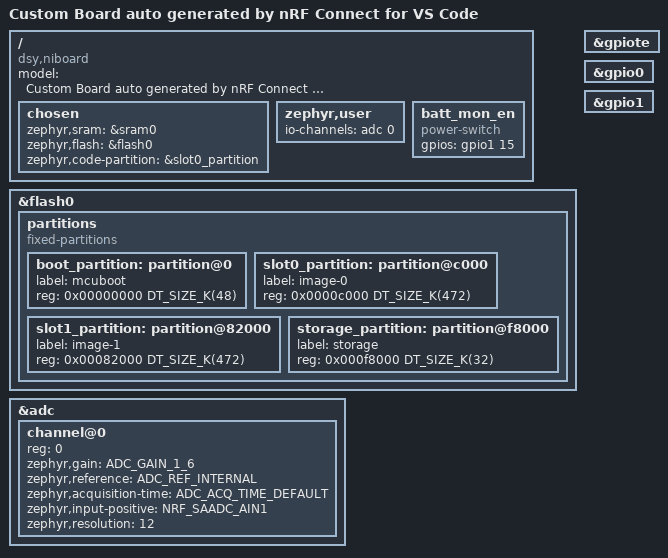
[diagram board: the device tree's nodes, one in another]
/dts-v1/;
#include <nordic/nrf52840_qfaa.dtsi>


/ {
	model = "Custom Board auto generated by nRF Connect for VS Code";
	compatible = "dsy,niboard";

	chosen {
		zephyr,sram = &sram0;
		zephyr,flash = &flash0;
		zephyr,code-partition = &slot0_partition;
	};
	zephyr,user {
        io-channels = <&adc 0>;
    };

	batt_mon_en: batt_mon_en {
		compatible = "power-switch";
        status = "okay";
		gpios= <&gpio1 15 GPIO_ACTIVE_HIGH>;
	};
};

&flash0 {
	partitions {
		compatible = "fixed-partitions";
		#address-cells = <1>;
		#size-cells = <1>;

		boot_partition: partition@0 {
			label = "mcuboot";
			reg = <0x00000000 DT_SIZE_K(48)>;
		};

		slot0_partition: partition@c000 {
			label = "image-0";
			reg = <0x0000c000 DT_SIZE_K(472)>;
		};

		slot1_partition: partition@82000 {
			label = "image-1";
			reg = <0x00082000 DT_SIZE_K(472)>;
		};

		storage_partition: partition@f8000 {
			label = "storage";
			reg = <0x000f8000 DT_SIZE_K(32)>;
		};
	};
};

&adc {
	#address-cells = <1>;
	#size-cells = <0>;
	status = "okay";
	channel@0 {
		reg = <0>;
		zephyr,gain = "ADC_GAIN_1_6";
		zephyr,reference = "ADC_REF_INTERNAL";
		zephyr,acquisition-time = <ADC_ACQ_TIME_DEFAULT>;
		zephyr,input-positive = <NRF_SAADC_AIN1>; 
		zephyr,resolution = <12>;
	};
};


&gpiote {
	status = "okay";
};

&gpio0 {
	status = "okay";
};
&gpio1 {
	status = "okay";
};



